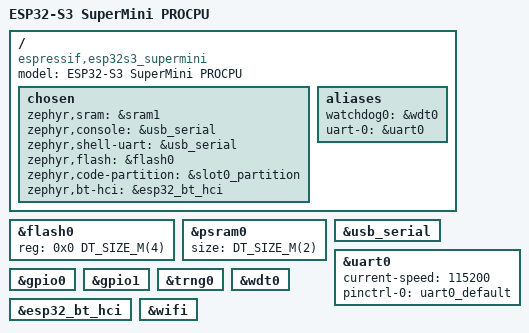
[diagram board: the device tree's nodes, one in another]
/*
 * Copyright (c) 2026 The ZMK Contributors
 *
 * SPDX-License-Identifier: MIT
 */

/dts-v1/;

#include <espressif/esp32s3/esp32s3.dtsi>
#include "esp32s3_supermini_esp32s3_procpu-pinctrl.dtsi"
#include <espressif/partitions_0x0_default_4M.dtsi>

/*
 * ESP32-S3 SuperMini (PROCPU only), qualified only against a board marked
 * ESP32-S3FH4R2: 4 MB flash + 2 MB QSPI PSRAM, USB-C on the internal PHY in
 * Serial/JTAG mode (GPIO19/20) for console, flash and recovery, UART0
 * (GPIO43/44) as backup. Other SuperMini clones are untested. PSRAM is
 * declared but unused (no CONFIG_ESP_SPIRAM) until validated on this part.
 */

/* Geometry the removed esp32s3_wroom_n4r2.dtsi used to provide (4 MB / 2 MB). */
&flash0 {
    reg = <0x0 DT_SIZE_M(4)>;
};

&psram0 {
    size = <DT_SIZE_M(2)>;
};

/ {
    model = "ESP32-S3 SuperMini PROCPU";
    compatible = "espressif,esp32s3_supermini";

    chosen {
        zephyr,sram = &sram1;
        zephyr,console = &usb_serial;
        zephyr,shell-uart = &usb_serial;
        zephyr,flash = &flash0;
        zephyr,code-partition = &slot0_partition;
        zephyr,bt-hci = &esp32_bt_hci;
    };

    aliases {
        watchdog0 = &wdt0;
        uart-0 = &uart0;
    };
};

&usb_serial {
    status = "okay";
};

&uart0 {
    status = "okay";
    current-speed = <115200>;
    pinctrl-0 = <&uart0_default>;
    pinctrl-names = "default";
};

&gpio0 {
    status = "okay";
};

&gpio1 {
    status = "okay";
};

&trng0 {
    status = "okay";
};

&wdt0 {
    status = "okay";
};

&esp32_bt_hci {
    status = "okay";
};

&wifi {
    status = "okay";
};
